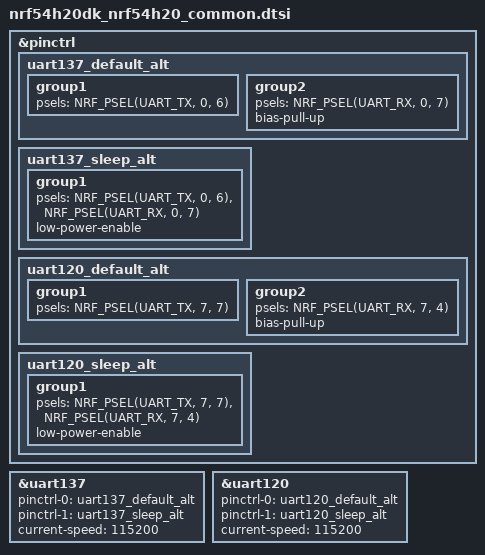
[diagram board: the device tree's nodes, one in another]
/* SPDX-License-Identifier: Apache-2.0 */

&pinctrl {
	uart137_default_alt: uart137_default_alt {
		group1 {
			psels = <NRF_PSEL(UART_TX, 0, 6)>;
		};
		group2 {
			psels = <NRF_PSEL(UART_RX, 0, 7)>;
			bias-pull-up;
		};
	};

	uart137_sleep_alt: uart137_sleep_alt {
		group1 {
			psels = <NRF_PSEL(UART_TX, 0, 6)>,
				<NRF_PSEL(UART_RX, 0, 7)>;
			low-power-enable;
		};
	};
	uart120_default_alt: uart120_default_alt {
		group1 {
			psels = <NRF_PSEL(UART_TX, 7, 7)>;
		};
		group2 {
			psels = <NRF_PSEL(UART_RX, 7, 4)>;
			bias-pull-up;
		};
	};

	uart120_sleep_alt: uart120_sleep_alt {
		group1 {
			psels = <NRF_PSEL(UART_TX, 7, 7)>,
				<NRF_PSEL(UART_RX, 7, 4)>;
			low-power-enable;
		};
	};
};

dut: &uart137 {
	status = "okay";
	pinctrl-0 = <&uart137_default_alt>;
	pinctrl-1 = <&uart137_sleep_alt>;
	pinctrl-names = "default", "sleep";
	current-speed = <115200>;
};

dut2: &uart120 {
	pinctrl-0 = <&uart120_default_alt>;
	pinctrl-1 = <&uart120_sleep_alt>;
	pinctrl-names = "default", "sleep";
	current-speed = <115200>;
};
